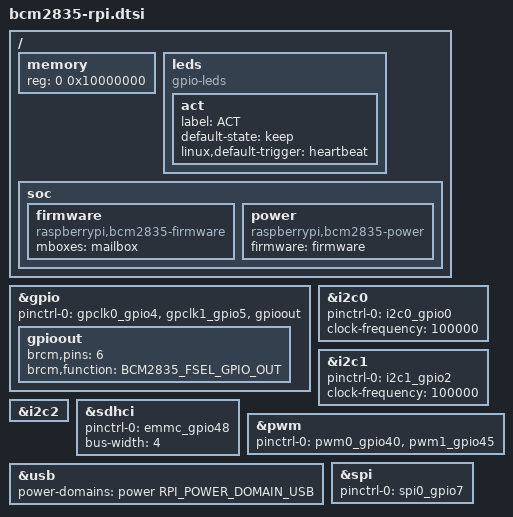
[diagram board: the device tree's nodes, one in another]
#include <dt-bindings/power/raspberrypi-power.h>

/ {
	memory {
		reg = <0 0x10000000>;
	};

	leds {
		compatible = "gpio-leds";

		act {
			label = "ACT";
			default-state = "keep";
			linux,default-trigger = "heartbeat";
		};
	};

	soc {
		firmware: firmware {
			compatible = "raspberrypi,bcm2835-firmware";
			mboxes = <&mailbox>;
		};

		power: power {
			compatible = "raspberrypi,bcm2835-power";
			firmware = <&firmware>;
			#power-domain-cells = <1>;
		};
	};
};

&gpio {
	pinctrl-names = "default";
	pinctrl-0 = <&gpclk0_gpio4
		     &gpclk1_gpio5
		     &gpioout>;

	gpioout: gpioout {
		brcm,pins = <6>;
		brcm,function = <BCM2835_FSEL_GPIO_OUT>;
	};
};

&i2c0 {
	pinctrl-names = "default";
	pinctrl-0 = <&i2c0_gpio0>;

	status = "okay";
	clock-frequency = <100000>;
};

&i2c1 {
	pinctrl-names = "default";
	pinctrl-0 = <&i2c1_gpio2>;

	status = "okay";
	clock-frequency = <100000>;
};

&i2c2 {
	status = "okay";
};

&sdhci {
	pinctrl-names = "default";
	pinctrl-0 = <&emmc_gpio48>;

	status = "okay";
	bus-width = <4>;
};

&pwm {
	pinctrl-names = "default";
	pinctrl-0 = <&pwm0_gpio40 &pwm1_gpio45>;

	status = "okay";
};

&usb {
	power-domains = <&power RPI_POWER_DOMAIN_USB>;
};

&spi {
	pinctrl-names = "default";
	pinctrl-0 = <&spi0_gpio7>;
};
